VERSION ""

NS_ :

BS_:

BU_: Tester ABS PCM BCM
VAL_TABLE_ EngineStatus 1 "Running" 0 "OFF" ;
VAL_TABLE_ VtPCMIgnON 1 "YES" 0 "NO" ;

BO_ 3221225472 VECTOR__INDEPENDENT_SIG_MSG: 0 Vector__XXX
 SG_ PCM_IgnitionON : 0|1@1- (1,0) [0|1] "" Vector__XXX

BO_ 258 Speed: 2 PCM
 SG_ VehicleSpeed : 0|16@1- (1,0) [0|255] ""  BCM

BO_ 1576 CANTPRx: 8 ABS
 SG_ CANTPRx : 0|64@1+ (1,0) [0|0] ""  BCM

BO_ 1568 CANTPTx: 8 BCM
 SG_ CANTPTx : 0|64@1+ (1,0) [0|0] ""  ABS

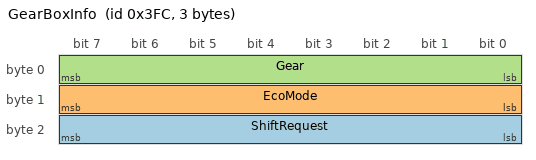
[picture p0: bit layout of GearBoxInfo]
BO_ 1020 GearBoxInfo: 3 PCM
 SG_ ShiftRequest : 16|8@1- (1,0) [0|1] "" Vector__XXX
 SG_ EcoMode : 8|8@1- (1,0) [0|0] "" Vector__XXX
 SG_ Gear : 0|8@1- (1,0) [0|0] "" Vector__XXX

BO_ 257 EngineStatus: 8 PCM
 SG_ ErrorCode : 2|6@1- (1,0) [0|0] "" Vector__XXX
 SG_ Status : 0|2@1- (1,0) [0|0] "" Vector__XXX

BO_ 513 ABSData: 1 ABS
 SG_ MainBrakePressure : 0|8@1- (1,-20) [-20|300] "bar"  BCM

BO_ 100 EngineData: 8 PCM
 SG_ EngSpeed : 0|16@1+ (1,0) [0|8000] "rpm" Vector__XXX
 SG_ PetrolLevel : 24|8@1- (1,0) [0|0] "" Vector__XXX
 SG_ IdleRunning : 23|1@1+ (1,0) [0|1] "" Vector__XXX
 SG_ EngineTemp : 16|8@1+ (0.15,0) [0|38.25] "Deg C"  BCM
 SG_ EnginePower : 48|16@1- (1,0) [0|0] ""  BCM
 SG_ EngForce : 32|16@1- (1,0) [0|0] ""  BCM

EV_ EnvEnginePower: 0 [0|0] "" 0 1 DUMMY_NODE_VECTOR0 Vector__XXX;

EV_ EnvEngineForce: 0 [0|0] "" 0 2 DUMMY_NODE_VECTOR0 Vector__XXX;

EV_ Env_teststring: 0 [0|0] "" 0 3 DUMMY_NODE_VECTOR8000 Vector__XXX;

EV_ EnvEngTemp: 0 [0|256] "" 0 4 DUMMY_NODE_VECTOR0 Vector__XXX;

EV_ ev_integer: 0 [0|0] "" 0 5 DUMMY_NODE_VECTOR0 Vector__XXX;

CM_ BO_ 3221225472 "This is a message for not used signals, created by Vector CANdb++ DBC OLE DB Provider.";
BA_DEF_ SG_  "GenSigEnvVarType" ENUM  "int","float","undef";
BA_DEF_ SG_  "GenSigStartValue" FLOAT -100000000000 100000000000;
BA_DEF_ SG_  "GenSigSendType" ENUM  "Cyclic","Event","EventPeriodic";
BA_DEF_ BO_  "GenMsgSendType" ENUM  "Cyclic","Event","Event Periodic";
BA_DEF_ BO_  "GenMsgCycleTime" INT 0 50000;
BA_DEF_ BO_  "GenMsgDelayTime" INT 1 1000;
BA_DEF_ BO_  "GenMsgCycleTimeFast" INT 2 50000;
BA_DEF_ BO_  "GenMsgILSupport" ENUM  "No","Yes";
BA_DEF_ BU_  "NodeLayerModules" STRING ;
BA_DEF_ BU_  "TpTxIdentifier" HEX 1536 1791;
BA_DEF_ BU_  "TpRxIdentifier" HEX 1536 1791;
BA_DEF_ BU_  "TpRxMask" HEX 0 255;
BA_DEF_ BU_  "TpCanBus" INT 0 2;
BA_DEF_ BU_  "TpUseFC" INT 0 1;
BA_DEF_ BU_  "TpNodeBaseAddress" HEX 0 33554431;
BA_DEF_ BU_  "NmStationAddress" INT 0 63;
BA_DEF_ BU_  "ILUsed" ENUM  "Yes","No";
BA_DEF_  "GenEnvVarEndingDsp" STRING ;
BA_DEF_  "GenEnvVarEndingSnd" STRING ;
BA_DEF_  "GenEnvVarPrefix" STRING ;
BA_DEF_  "GenNWMTalkNM" STRING ;
BA_DEF_  "GenNWMGotoMode_BusSleep" STRING ;
BA_DEF_  "GenNWMGotoMode_Awake" STRING ;
BA_DEF_  "GenNWMApCanSleep" STRING ;
BA_DEF_  "GenNWMApCanOn" STRING ;
BA_DEF_  "GenNWMApCanOff" STRING ;
BA_DEF_  "NmBaseAddress" HEX 1280 1311;
BA_DEF_  "DBName" STRING ;
BA_DEF_DEF_  "GenSigEnvVarType" "undef";
BA_DEF_DEF_  "GenSigStartValue" 0;
BA_DEF_DEF_  "GenSigSendType" "Cyclic";
BA_DEF_DEF_  "GenMsgSendType" "Cyclic";
BA_DEF_DEF_  "GenMsgCycleTime" 0;
BA_DEF_DEF_  "GenMsgDelayTime" 1;
BA_DEF_DEF_  "GenMsgCycleTimeFast" 100;
BA_DEF_DEF_  "GenMsgILSupport" "Yes";
BA_DEF_DEF_  "NodeLayerModules" "CANoeILNLVector";
BA_DEF_DEF_  "TpTxIdentifier" 1536;
BA_DEF_DEF_  "TpRxIdentifier" 1536;
BA_DEF_DEF_  "TpRxMask" 255;
BA_DEF_DEF_  "TpCanBus" 1;
BA_DEF_DEF_  "TpUseFC" 1;
BA_DEF_DEF_  "TpNodeBaseAddress" 1536;
BA_DEF_DEF_  "NmStationAddress" 0;
BA_DEF_DEF_  "ILUsed" "Yes";
BA_DEF_DEF_  "GenEnvVarEndingDsp" "Dsp_";
BA_DEF_DEF_  "GenEnvVarEndingSnd" "_";
BA_DEF_DEF_  "GenEnvVarPrefix" "Env";
BA_DEF_DEF_  "GenNWMTalkNM" "TalkNM()";
BA_DEF_DEF_  "GenNWMGotoMode_BusSleep" "GotoMode_BusSleep()";
BA_DEF_DEF_  "GenNWMGotoMode_Awake" "GotoMode_Awake()";
BA_DEF_DEF_  "GenNWMApCanSleep" "apCanSleep()";
BA_DEF_DEF_  "GenNWMApCanOn" "apCanOn()";
BA_DEF_DEF_  "GenNWMApCanOff" "apCanOff()";
BA_DEF_DEF_  "NmBaseAddress" 1280;
BA_DEF_DEF_  "DBName" "";
BA_ "DBName" "Sample_Database";
BA_ "NmStationAddress" BU_ Tester 4;
BA_ "NodeLayerModules" BU_ ABS "";
BA_ "ILUsed" BU_ ABS 1;
BA_ "NmStationAddress" BU_ ABS 2;
BA_ "NodeLayerModules" BU_ PCM "CANoeILNLVector,osek_tp.dll";
BA_ "NmStationAddress" BU_ PCM 3;
BA_ "NodeLayerModules" BU_ BCM "CANoeILNLVector,osek_tp.dll";
BA_ "NmStationAddress" BU_ BCM 1;
BA_ "GenMsgCycleTime" BO_ 258 250;
BA_ "GenMsgSendType" BO_ 1576 1;
BA_ "GenMsgSendType" BO_ 1568 1;
BA_ "GenMsgCycleTime" BO_ 1020 100;
BA_ "GenMsgCycleTime" BO_ 257 100;
BA_ "GenMsgCycleTime" BO_ 513 250;
BA_ "GenMsgCycleTime" BO_ 100 200;
VAL_ 3221225472 PCM_IgnitionON 1 "YES" 0 "NO" ;
VAL_ 257 Status 1 "Running" 0 "OFF" ;
